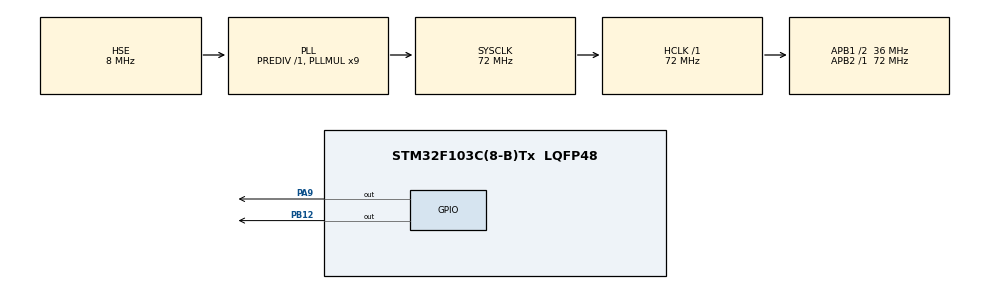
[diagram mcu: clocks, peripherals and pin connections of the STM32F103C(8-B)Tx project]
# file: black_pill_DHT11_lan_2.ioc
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Mcu.Family=STM32F1
Mcu.Name=STM32F103C(8-B)Tx
Mcu.Package=LQFP48
NVIC.PriorityGroup=NVIC_PRIORITYGROUP_4
PA13.Mode=Serial_Wire
PA13.Signal=SYS_JTMS-SWDIO
PA14.Mode=Serial_Wire
PA14.Signal=SYS_JTCK-SWCLK
PA9.Signal=GPIO_Output
PB12.Signal=GPIO_Output
PD0-OSC_IN.Mode=HSE-External-Oscillator
PD0-OSC_IN.Signal=RCC_OSC_IN
PD1-OSC_OUT.Mode=HSE-External-Oscillator
PD1-OSC_OUT.Signal=RCC_OSC_OUT
ProjectManager.HeapSize=0x200
ProjectManager.StackSize=0x400
ProjectManager.TargetToolchain=STM32CubeIDE
RCC.AHBFreq_Value=72000000
RCC.APB1CLKDivider=RCC_HCLK_DIV2
RCC.APB1Freq_Value=36000000
RCC.APB1TimFreq_Value=72000000
RCC.APB2Freq_Value=72000000
RCC.APB2TimFreq_Value=72000000
RCC.HCLKFreq_Value=72000000
RCC.PLLMUL=RCC_PLL_MUL9
RCC.PLLSourceVirtual=RCC_PLLSOURCE_HSE
RCC.SYSCLKFreq_VALUE=72000000
RCC.SYSCLKSource=RCC_SYSCLKSOURCE_PLLCLK
RCC.USBFreq_Value=72000000
TIM4.Period=0xffff-1
TIM4.Prescaler=72-1
VP_TIM4_VS_ClockSourceINT.Mode=Internal
board=custom

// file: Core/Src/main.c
/* USER CODE BEGIN Header */
/**
  ******************************************************************************
  * @file           : main.c
  * @brief          : Main program body
  ******************************************************************************
  * @attention
  *
  * <h2><center>&copy; Copyright (c) 2020 STMicroelectronics.
  * All rights reserved.</center></h2>
  *
  * This software component is licensed by ST under BSD 3-Clause license,
  * the "License"; You may not use this file except in compliance with the
  * License. You may obtain a copy of the License at:
  *                        opensource.org/licenses/BSD-3-Clause
  *
  ******************************************************************************
  */
/* USER CODE END Header */

#include "main.h"

TIM_HandleTypeDef htim4;

/* USER CODE BEGIN PV */
uint8_t int_RH,dec_RH,int_T,dec_T,Respones_State;
uint8_t Check_Sum;
/* USER CODE END PV */

void SystemClock_Config(void);
static void MX_GPIO_Init(void);
static void MX_TIM4_Init(void);

/* USER CODE BEGIN 0 */
void DHT11_Start (void)
{
	Set_Pin_Output (GPIOB,GPIO_PIN_12);  // set the pin as output
	HAL_GPIO_WritePin (GPIOB, GPIO_PIN_12, 0);    // pull the pin low
	delay (18000);   // wait for 18ms
	Set_Pin_Input(GPIOA,GPIO_PIN_12);    // set as input
}

 uint16_t counter;
/* USER CODE END 0 */

int main(void)
{

  /* MCU Configuration--------------------------------------------------------*/

  /* Reset of all peripherals, Initializes the Flash interface and the Systick. */
  HAL_Init();

  /* Configure the system clock */
  SystemClock_Config();

  /* Initialize all configured peripherals */
  MX_GPIO_Init();
  MX_TIM4_Init();
  /* USER CODE BEGIN 2 */
  HAL_TIM_Base_Start(&htim4);

  /* USER CODE END 2 */

  /* Infinite loop */
  /* USER CODE BEGIN WHILE */
  while (1)
  {
	  DHT_Start();
	  Respones_State = DHT_Check_Response();
	  int_RH = DHT_Read_Data();
	  dec_RH = DHT_Read_Data();
	  int_T  = DHT_Read_Data();
	  dec_T	 = DHT_Read_Data();
	  Check_Sum = DHT_Read_Data();
	  HAL_GPIO_TogglePin(GPIOA,GPIO_PIN_9);
	  HAL_Delay(500);
    /* USER CODE END WHILE */

  }
}

void SystemClock_Config(void)
{
  RCC_OscInitTypeDef RCC_OscInitStruct = {0};
  RCC_ClkInitTypeDef RCC_ClkInitStruct = {0};

  /** Initializes the CPU, AHB and APB busses clocks
  */
  RCC_OscInitStruct.OscillatorType = RCC_OSCILLATORTYPE_HSE;
  RCC_OscInitStruct.HSEState = RCC_HSE_ON;
  RCC_OscInitStruct.HSEPredivValue = RCC_HSE_PREDIV_DIV1;
  RCC_OscInitStruct.HSIState = RCC_HSI_ON;
  RCC_OscInitStruct.PLL.PLLState = RCC_PLL_ON;
  RCC_OscInitStruct.PLL.PLLSource = RCC_PLLSOURCE_HSE;
  RCC_OscInitStruct.PLL.PLLMUL = RCC_PLL_MUL9;
  if (HAL_RCC_OscConfig(&RCC_OscInitStruct) != HAL_OK)
  {
    Error_Handler();
  }
  /** Initializes the CPU, AHB and APB busses clocks
  */
  RCC_ClkInitStruct.ClockType = RCC_CLOCKTYPE_HCLK|RCC_CLOCKTYPE_SYSCLK
                              |RCC_CLOCKTYPE_PCLK1|RCC_CLOCKTYPE_PCLK2;
  RCC_ClkInitStruct.SYSCLKSource = RCC_SYSCLKSOURCE_PLLCLK;
  RCC_ClkInitStruct.AHBCLKDivider = RCC_SYSCLK_DIV1;
  RCC_ClkInitStruct.APB1CLKDivider = RCC_HCLK_DIV2;
  RCC_ClkInitStruct.APB2CLKDivider = RCC_HCLK_DIV1;

  if (HAL_RCC_ClockConfig(&RCC_ClkInitStruct, FLASH_LATENCY_2) != HAL_OK)
  {
    Error_Handler();
  }
}

static void MX_TIM4_Init(void)
{

  TIM_ClockConfigTypeDef sClockSourceConfig = {0};
  TIM_MasterConfigTypeDef sMasterConfig = {0};

  htim4.Instance = TIM4;
  htim4.Init.Prescaler = 72-1;
  htim4.Init.CounterMode = TIM_COUNTERMODE_UP;
  htim4.Init.Period = 0xffff-1;
  htim4.Init.ClockDivision = TIM_CLOCKDIVISION_DIV1;
  htim4.Init.AutoReloadPreload = TIM_AUTORELOAD_PRELOAD_DISABLE;
  if (HAL_TIM_Base_Init(&htim4) != HAL_OK)
  {
    Error_Handler();
  }
  sClockSourceConfig.ClockSource = TIM_CLOCKSOURCE_INTERNAL;
  if (HAL_TIM_ConfigClockSource(&htim4, &sClockSourceConfig) != HAL_OK)
  {
    Error_Handler();
  }
  sMasterConfig.MasterOutputTrigger = TIM_TRGO_RESET;
  sMasterConfig.MasterSlaveMode = TIM_MASTERSLAVEMODE_DISABLE;
  if (HAL_TIMEx_MasterConfigSynchronization(&htim4, &sMasterConfig) != HAL_OK)
  {
    Error_Handler();
  }

}

static void MX_GPIO_Init(void)
{
  GPIO_InitTypeDef GPIO_InitStruct = {0};

  /* GPIO Ports Clock Enable */
  __HAL_RCC_GPIOD_CLK_ENABLE();
  __HAL_RCC_GPIOB_CLK_ENABLE();
  __HAL_RCC_GPIOA_CLK_ENABLE();

  /*Configure GPIO pin Output Level */
  HAL_GPIO_WritePin(GPIOB, GPIO_PIN_12, GPIO_PIN_RESET);

  /*Configure GPIO pin Output Level */
  HAL_GPIO_WritePin(GPIOA, GPIO_PIN_9, GPIO_PIN_RESET);

  /*Configure GPIO pin : PB12 */
  GPIO_InitStruct.Pin = GPIO_PIN_12;
  GPIO_InitStruct.Mode = GPIO_MODE_OUTPUT_PP;
  GPIO_InitStruct.Pull = GPIO_NOPULL;
  GPIO_InitStruct.Speed = GPIO_SPEED_FREQ_LOW;
  HAL_GPIO_Init(GPIOB, &GPIO_InitStruct);

  /*Configure GPIO pin : PA9 */
  GPIO_InitStruct.Pin = GPIO_PIN_9;
  GPIO_InitStruct.Mode = GPIO_MODE_OUTPUT_PP;
  GPIO_InitStruct.Pull = GPIO_NOPULL;
  GPIO_InitStruct.Speed = GPIO_SPEED_FREQ_LOW;
  HAL_GPIO_Init(GPIOA, &GPIO_InitStruct);

}

/* USER CODE BEGIN 4 */
void delay (uint16_t time)
 {
 	__HAL_TIM_SET_COUNTER(&htim4,0);
 	while(__HAL_TIM_GET_COUNTER(&htim4)<time);

 }
 uint8_t Rh_byte1,Rh_byte2,Temp_byte1,Temp_byte2;
 uint16_t SUM,RH,TEMP;
 float temperature;
 float humidity;
 uint8_t presence;
 void Set_Pin_Output(GPIO_TypeDef *GPIOx, uint16_t GPIO_Pin)
 {
 	GPIO_InitTypeDef GPIO_InitStruct = {0};

 	GPIO_InitStruct.Pin = GPIO_Pin;
 	GPIO_InitStruct.Mode = GPIO_MODE_OUTPUT_PP;
 	GPIO_InitStruct.Pull = GPIO_NOPULL;
 	GPIO_InitStruct.Speed = GPIO_SPEED_FREQ_LOW;
 	HAL_GPIO_Init(GPIOx, &GPIO_InitStruct);
 }

 void Set_Pin_Input(GPIO_TypeDef *GPIOx, uint16_t GPIO_Pin)
 {
 	GPIO_InitTypeDef GPIO_InitStruct = {0};

 	GPIO_InitStruct.Pin = GPIO_Pin;
 	GPIO_InitStruct.Mode = GPIO_MODE_INPUT;
 	GPIO_InitStruct.Pull = GPIO_NOPULL;
 	HAL_GPIO_Init(GPIOx, &GPIO_InitStruct);
 }

 uint8_t Check_Response (void)
 {
 	uint8_t Response = 0;
 	delay (40);
 	if (!(HAL_GPIO_ReadPin (GPIOB, GPIO_PIN_12)))
 	{
 		delay (80);
 		if ((HAL_GPIO_ReadPin (GPIOB, GPIO_PIN_12))) Response = 1;
 		else Response = -1;
 	}
 	while ((HAL_GPIO_ReadPin (GPIOB, GPIO_PIN_12)));   // wait for the pin to go low

 	return Response;
 }
 uint8_t DHT11_Read (void)
 {
 	uint8_t i,j;
 	for (j=0;j<8;j++)
 	{
 		while (!(HAL_GPIO_ReadPin (GPIOB, GPIO_PIN_12)));   // wait for the pin to go high
 		delay (40);   // wait for 40 us
 		if (!(HAL_GPIO_ReadPin (GPIOB, GPIO_PIN_12)))   // if the pin is low
 		{
 			i&= ~(1<<(7-j));   // write 0
 		}
 		else i|= (1<<(7-j));  // if the pin is high, write 1
 		while ((HAL_GPIO_ReadPin (GPIOB, GPIO_PIN_12)));  // wait for the pin to go low
 	}
 	return i;
 }

/* USER CODE END 4 */

void Error_Handler(void)
{
}

/************************ (C) COPYRIGHT STMicroelectronics *****END OF FILE****/
